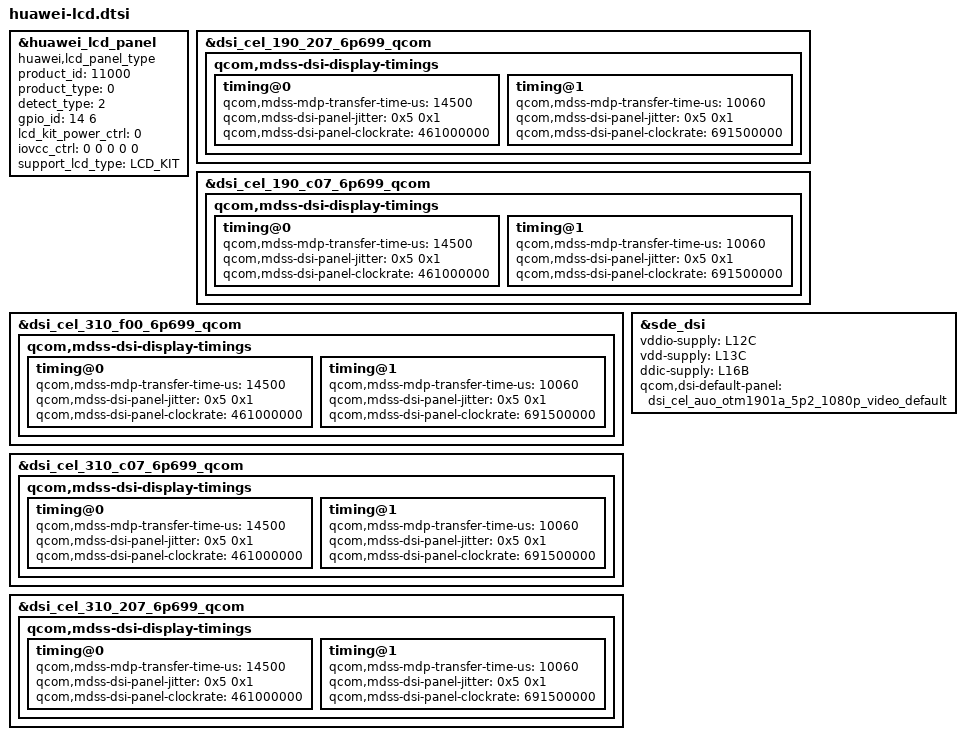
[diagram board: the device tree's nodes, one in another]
#include "../../../lcdkit3.0/cel/devkit_lcd_kit.dtsi"
&huawei_lcd_panel {
	compatible = "huawei,lcd_panel_type";
	/* auto_key_info @ name: product_id type: uint32 default: 0 */
	product_id = <11000>;
	/* auto_key_info @ name: product_type type: uint32 default: 0 */
	product_type = <0>;
	detect_type = <2>;
	/* auto_key_info @ name: gpio_id[2] type: int default: 0 */
	gpio_id = <14 6>;
	/* auto_key_info @ name: lcd_kit_power_ctrl type: uint32 default: 0 */
	lcd_kit_power_ctrl = <0>;
	/* iovcc_ctrl: byte-1:power mode(1:ldo, 2:gpio), byte-2: pmic id,  byte-3: ldo id, byte-4: ldo value, byte-5: delay */
	/* auto_key_info @ name: iovcc_ctrl[5] type: uint32 default: 0 */
	iovcc_ctrl = <0 0 0 0 0>;
	support_lcd_type = "LCD_KIT";
};

&dsi_cel_190_207_6p699_qcom {
	qcom,mdss-dsi-display-timings {
		timing@0 {
			qcom,mdss-mdp-transfer-time-us = <14500>;
			qcom,mdss-dsi-panel-jitter = <0x5 0x1>;
			qcom,mdss-dsi-panel-clockrate = <461000000>;
		};
		timing@1 {
			qcom,mdss-mdp-transfer-time-us = <10060>;
			qcom,mdss-dsi-panel-jitter = <0x5 0x1>;
			qcom,mdss-dsi-panel-clockrate = <691500000>;
		};
	};
};
&dsi_cel_190_c07_6p699_qcom {
	qcom,mdss-dsi-display-timings {
		timing@0 {
			qcom,mdss-mdp-transfer-time-us = <14500>;
			qcom,mdss-dsi-panel-jitter = <0x5 0x1>;
			qcom,mdss-dsi-panel-clockrate = <461000000>;
		};
		timing@1 {
			qcom,mdss-mdp-transfer-time-us = <10060>;
			qcom,mdss-dsi-panel-jitter = <0x5 0x1>;
			qcom,mdss-dsi-panel-clockrate = <691500000>;
		};
	};
};
&dsi_cel_310_f00_6p699_qcom {
	qcom,mdss-dsi-display-timings {
		timing@0 {
			qcom,mdss-mdp-transfer-time-us = <14500>;
			qcom,mdss-dsi-panel-jitter = <0x5 0x1>;
			qcom,mdss-dsi-panel-clockrate = <461000000>;
		};
		timing@1 {
			qcom,mdss-mdp-transfer-time-us = <10060>;
			qcom,mdss-dsi-panel-jitter = <0x5 0x1>;
			qcom,mdss-dsi-panel-clockrate = <691500000>;
		};
	};
};
&dsi_cel_310_c07_6p699_qcom {
	qcom,mdss-dsi-display-timings {
		timing@0 {
			qcom,mdss-mdp-transfer-time-us = <14500>;
			qcom,mdss-dsi-panel-jitter = <0x5 0x1>;
			qcom,mdss-dsi-panel-clockrate = <461000000>;
		};
		timing@1 {
			qcom,mdss-mdp-transfer-time-us = <10060>;
			qcom,mdss-dsi-panel-jitter = <0x5 0x1>;
			qcom,mdss-dsi-panel-clockrate = <691500000>;
		};
	};
};
&dsi_cel_310_207_6p699_qcom {
	qcom,mdss-dsi-display-timings {
		timing@0 {
			qcom,mdss-mdp-transfer-time-us = <14500>;
			qcom,mdss-dsi-panel-jitter = <0x5 0x1>;
			qcom,mdss-dsi-panel-clockrate = <461000000>;
		};
		timing@1 {
			qcom,mdss-mdp-transfer-time-us = <10060>;
			qcom,mdss-dsi-panel-jitter = <0x5 0x1>;
			qcom,mdss-dsi-panel-clockrate = <691500000>;
		};
	};
};

&sde_dsi {
	vddio-supply = <&L12C>;
	vdd-supply = <&L13C>;
	ddic-supply = <&L16B>;
	qcom,dsi-default-panel = <&dsi_cel_auo_otm1901a_5p2_1080p_video_default>;
};
